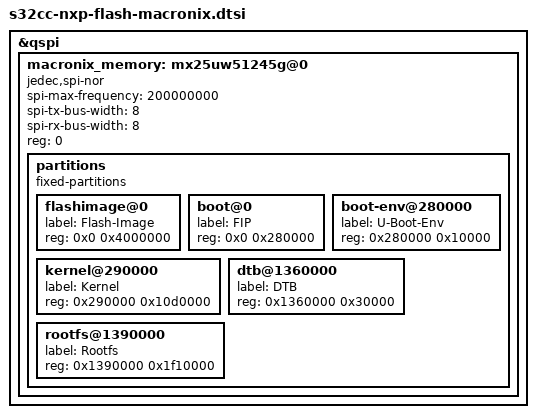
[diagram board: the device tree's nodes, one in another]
// SPDX-License-Identifier: (GPL-2.0+ OR BSD-3-Clause)
/*
 * Copyright 2022-2024 NXP
 */

&qspi {
	macronix_memory: mx25uw51245g@0 {
		compatible = "jedec,spi-nor";
		spi-max-frequency = <200000000>;
		spi-tx-bus-width = <8>;
		spi-rx-bus-width = <8>;
		reg = <0>;

		partitions {
			compatible = "fixed-partitions";
			#address-cells = <1>;
			#size-cells = <1>;

			flashimage@0 {
				label = "Flash-Image";
				reg = <0x0 0x4000000>;
			};

			boot@0 {
				label = "FIP";
				reg = <0x0 0x280000>;
			};

			boot-env@280000 {
				label = "U-Boot-Env";
				reg = <0x280000 0x10000>;
			};

			kernel@290000 {
				label = "Kernel";
				reg = <0x290000 0x10d0000>;
			};

			dtb@1360000 {
				label = "DTB";
				reg = <0x1360000 0x30000>;
			};

			rootfs@1390000 {
				label = "Rootfs";
				reg = <0x1390000 0x1f10000>;
			};
		};
	};
};
